# ADSP-2183xW_LPC register map
Vendor: Analog Devices; Series: ADSP-2183xW_LPC; File version: 3.0.3.517
CPU: 
Registers are 32-bit, read-write, reset 0x0 unless marked. A register's access mark holds for its fields unless they carry their own. Offsets are from the block's base; [hi:lo] are bit positions; {n}, {i} and the like mark numbered series; 'fields as' and 'values as' point back to an identical list.

## SEC0 — System Event Controller
Base 0x31089000
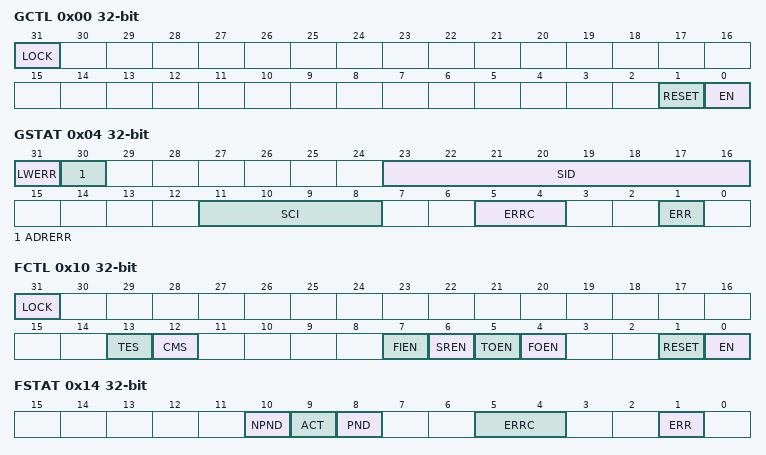
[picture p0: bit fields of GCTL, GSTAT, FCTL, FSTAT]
0x00 GCTL — Global Control Register
  [31] LOCK
    0=UNLOCK; 1=LOCK
  [1] RESET
    0=NO_RESET (No Action); 1=RESET
  [0] EN — Enable
    0=DIS (Disable); 1=EN (Enable)
0x04 GSTAT — Global Status Register
  [31] LWERR — Lock Write Error
    0=NO_LWERR (No Error); 1=LWERR (Error Occurred)
  [30] ADRERR — Address Error
    0=NO_ADRERR (No Error); 1=ADRERR (Error Occurred)
  [23:16] SID ro — Source ID for SSI Error
  [11:8] SCI ro — SCI ID for SCI Error
  [5:4] ERRC ro — Error Cause
    0=SFIERR (SFI Error); 1=SCIERR (SCI Error); 2=SSIERR (SSI Error)
  [1] ERR — Error
    0=NO_ERR (No Error); 1=ERR (Error Occurred)
0x08 RAISE — Global Raise Register
  [7:0] SID range 0x00000000..0x000000FF — Source ID
0x0C END — Global End Register
  [7:0] SID range 0x00000000..0x000000FF — Source ID IRQ to End
0x10 FCTL — Fault Control Register
  [31] LOCK
    0=UNLOCK; 1=LOCK
  [13] TES — Trigger Event Select
    0=FLTACT_MODE (Fault Active Mode); 1=FLTPND_MODE (Fault Pending Mode)
  [12] CMS — COP Mode Select
    0=FLT_MODE (Fault Mode); 1=COP_MODE
  [7] FIEN — Fault Input Enable
    0=FLTIN_DIS (Disable); 1=FLTIN_EN (Enable)
  [6] SREN — System Reset Enable
    0=SYSRST_DIS (Disable); 1=SYSRST_EN (Enable)
  [5] TOEN — Trigger Output Enable
    0=TRGOUT_DIS (Disable); 1=TRGOUT_EN (Enable)
  [4] FOEN — Fault Output Enable
    0=FLTOUT_DIS (Disable); 1=FLTOUT_EN (Enable)
  [1] RESET
    0=NO_RESET (No Action); 1=RESET
  [0] EN — Enable
    0=DIS (Disable); 1=EN (Enable)
0x14 FSTAT — Fault Status Register
  [10] NPND ro — Next Pending Fault
    0=NO_NXTFLT (Not Pending); 1=NXTFLT (Pending)
  [9] ACT ro — Fault Active
    0=NO_FLTACT (No Fault); 1=FLTACT (Active Fault)
  [8] PND ro — Pending Fault
    0=NO_FLTPND (Not Pending); 1=FLTPND (Pending)
  [5:4] ERRC ro — Error Cause
    0=SOVFERR (Source Overflow Error); 2=ENDERR (End Error)
  [1] ERR — Error
    0=NO_ERR (No Error); 1=ERR (Error Occurred)
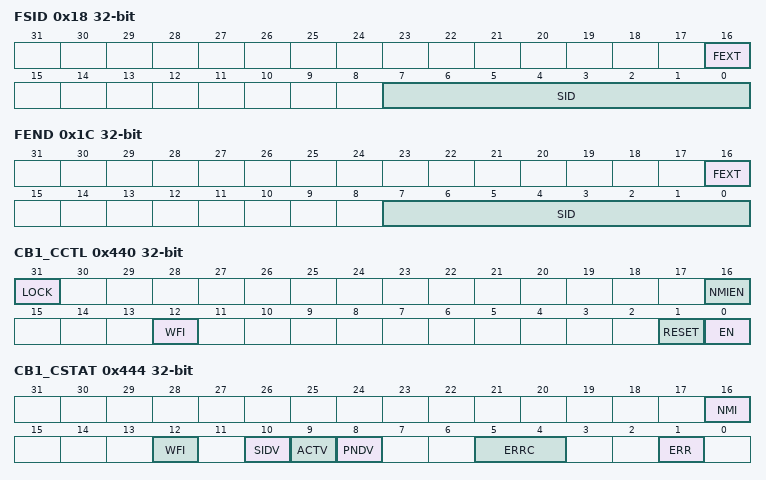
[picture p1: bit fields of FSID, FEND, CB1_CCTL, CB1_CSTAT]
0x18 FSID — Fault Source ID Register
  [16] FEXT ro — Fault External
    0=SRC_INTFLT (Fault Internal); 1=SRC_EXTFLT (Fault External)
  [7:0] SID ro — Source ID
0x1C FEND — Fault End Register
  [16] FEXT — Fault External
    0=END_INTFLT (Fault Internal); 1=END_EXTFLT (Fault External)
  [7:0] SID range 0x00000000..0x000000FF — Source ID
0x20 FDLY — Fault Delay Register
  [31:0] COUNT range 0x00000000..0xFFFFFFFF — Fault Delay
0x24 FDLY_CUR — Fault Delay Current Register
  [31:0] COUNT ro — Fault Delay
0x28 FSRDLY — Fault System Reset Delay Register
  [31:0] COUNT range 0x00000000..0xFFFFFFFF — Fault System Reset Delay
0x2C FSRDLY_CUR — Fault System Reset Delay Current Register
  [31:0] COUNT ro — Fault System Reset Delay
0x30 FCOPP — Fault COP Period Register
  [31:0] COUNT range 0x00000000..0xFFFFFFFF — Fault COP Period
0x34 FCOPP_CUR — Fault COP Period Current Register
  [31:0] COUNT ro — Fault COP Period
0x440 CB1_CCTL — SCI Control Register n
  [31] LOCK
    0=UNLOCK; 1=LOCK
  [16] NMIEN — NMI Enable
    0=NMI_DIS (Disable); 1=NMI_EN (Enable)
  [12] WFI — Wait For Idle
    0=NO_WAITIDLE (No Action); 1=WAITIDLE (Wait for Idle)
  [1] RESET
    0=NO_RESET (No Action); 1=RESET
  [0] EN — Enable
    0=DIS (Disable); 1=EN (Enable)
0x444 CB1_CSTAT — SCI Status Register n
  [16] NMI — Non-Maskable Interrupt
    0=NO_NMI (No NMI Occurred); 1=NMI (NMI Occurred)
  [12] WFI — Wait For Idle
    0=NOT_WAITING; 1=WAITING
  [10] SIDV ro — SID Valid
    0=INVALID_SID; 1=VALID_SID
  [9] ACTV ro — ACT Valid
    0=INVALID_ACT; 1=VALID_ACT
  [8] PNDV ro — PND Valid
    0=INVALID_PND; 1=VALID_PND
  [5:4] ERRC ro — Error Cause
  [1] ERR — Error
    0=NO_ERR (No Error); 1=ERR (Error Occurred)
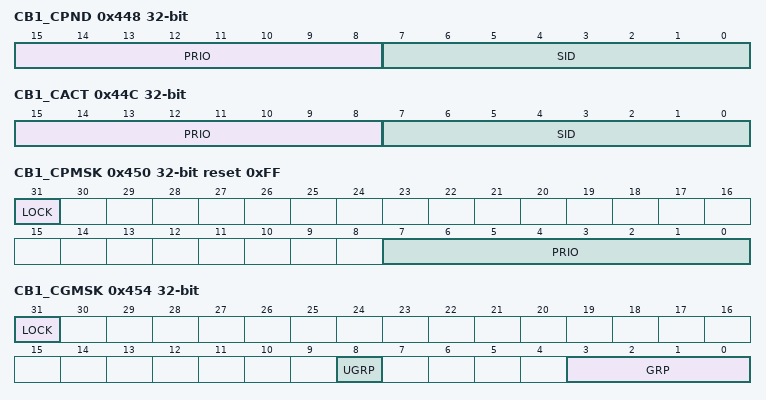
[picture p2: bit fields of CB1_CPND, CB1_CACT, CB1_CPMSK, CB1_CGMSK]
0x448 CB1_CPND — Core Pending Register n
  [15:8] PRIO ro — Highest Pending IRQ Priority
  [7:0] SID ro — Highest Pending IRQ Source ID
0x44C CB1_CACT — SCI Active Register n
  [15:8] PRIO ro — Highest Active IRQ Priority
  [7:0] SID ro — Highest Active IRQ Source ID
0x450 CB1_CPMSK reset 0xFF — SCI Priority Mask Register n
  [31] LOCK
    0=UNLOCK; 1=LOCK
  [7:0] PRIO — IRQ Priority Mask
0x454 CB1_CGMSK — SCI Group Mask Register n
  [31] LOCK
    0=UNLOCK; 1=LOCK
  [8] UGRP — Ungrouped Mask
    0=UNMASK (Unmask Ungrouped Sources); 1=MASK (Mask Ungrouped Sources)
  [3:0] GRP — Grouped Mask
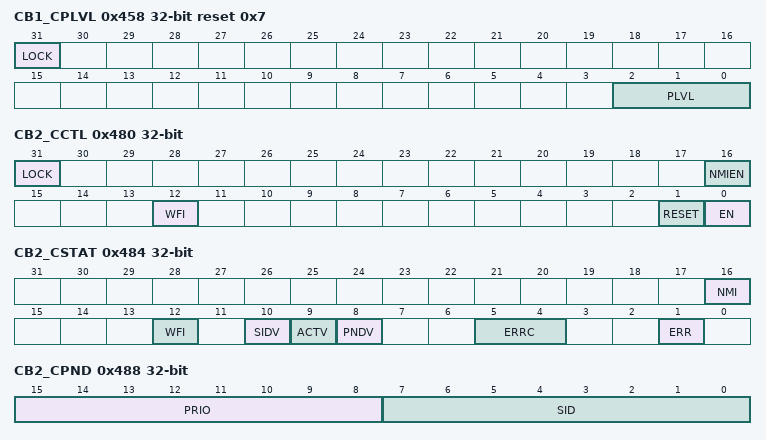
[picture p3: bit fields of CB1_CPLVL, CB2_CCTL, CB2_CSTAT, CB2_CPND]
0x458 CB1_CPLVL reset 0x7 — SCI Priority Level Register n
  [31] LOCK
    0=UNLOCK; 1=LOCK
  [2:0] PLVL — Priority Levels
0x45C CB1_CSID — SCI Source ID Register n
  [7:0] SID ro — Source ID
0x480 CB2_CCTL — SCI Control Register n
  fields as CB1_CCTL
0x484 CB2_CSTAT — SCI Status Register n
  fields as CB1_CSTAT
0x488 CB2_CPND — Core Pending Register n
  fields as CB1_CPND
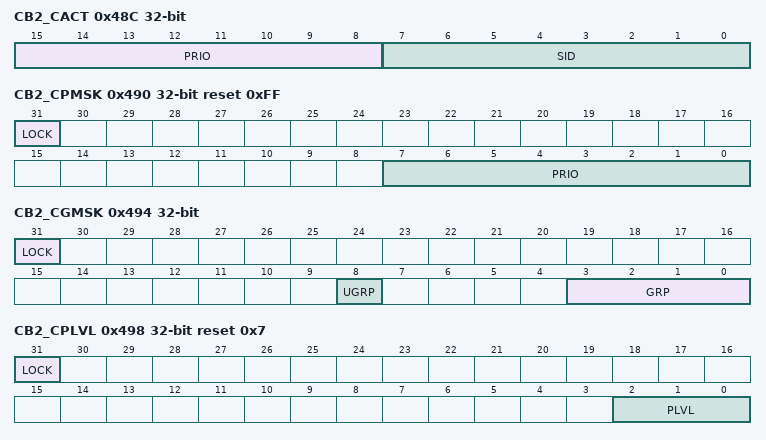
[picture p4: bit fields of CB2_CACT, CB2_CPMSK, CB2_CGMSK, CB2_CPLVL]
0x48C CB2_CACT — SCI Active Register n
  fields as CB1_CACT
0x490 CB2_CPMSK reset 0xFF — SCI Priority Mask Register n
  [31] LOCK
    0=UNLOCK; 1=LOCK
  [7:0] PRIO — IRQ Priority Mask
0x494 CB2_CGMSK — SCI Group Mask Register n
  fields as CB1_CGMSK
0x498 CB2_CPLVL reset 0x7 — SCI Priority Level Register n
  [31] LOCK
    0=UNLOCK; 1=LOCK
  [2:0] PLVL — Priority Levels
0x49C CB2_CSID — SCI Source ID Register n
  [7:0] SID ro — Source ID
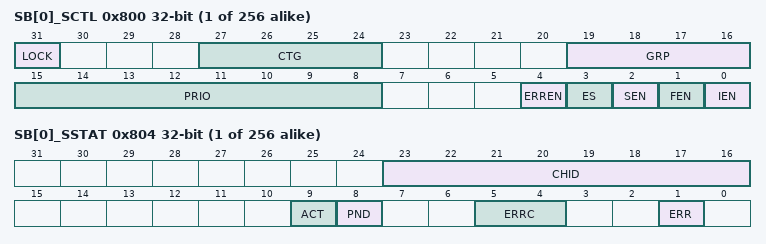
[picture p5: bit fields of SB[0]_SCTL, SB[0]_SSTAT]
{0x800+8i} SB[{i}]_SCTL (i=0..255) — Source Control Register n
  [31] LOCK
    0=UNLOCK; 1=LOCK
  [27:24] CTG — Core Target Select
  [19:16] GRP range 0x00000000..0x0000000F — Group Select
  [15:8] PRIO range 0x00000000..0x000000FF — Priority Level Select
  [4] ERREN — Error Enable
    0=ERR_DIS (Disable); 1=ERR_EN (Enable)
  [3] ES — Edge Select
    0=LEVEL (Level Sensitive); 1=EDGE (Edge Sensitive)
  [2] SEN — Source (signal) Enable
    0=SRC_DIS (Disable); 1=SRC_EN (Enable)
  [1] FEN — Fault Enable
    0=FAULT_DIS (Disable); 1=FAULT_EN (Enable)
  [0] IEN — Interrupt Enable
    0=INT_DIS (Disable); 1=INT_EN (Enable)
{0x804+8i} SB[{i}]_SSTAT (i=0..255) — Source Status Register n
  [23:16] CHID ro — Channel ID
  [9] ACT — Active Source
    0=NO_SRC (Not Active); 1=ACTIVE_SRC
  [8] PND — Pending Source
    0=NOTPENDING; 1=PENDING
  [5:4] ERRC ro — Error Cause
    0=SOVFERR (Source Overflow Error); 2=ENDERR (End Error)
  [1] ERR — Error
    0=NO_ERR (No Error); 1=ERR (Error Occurred)
